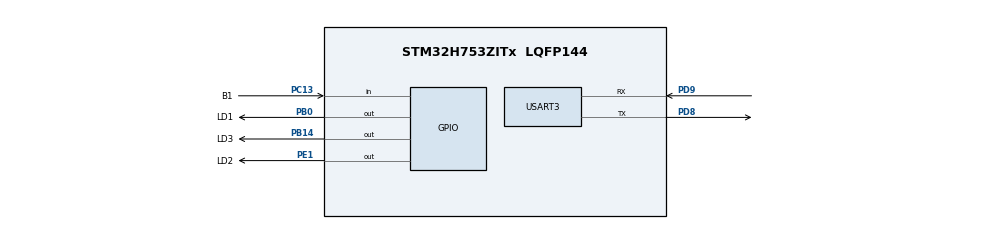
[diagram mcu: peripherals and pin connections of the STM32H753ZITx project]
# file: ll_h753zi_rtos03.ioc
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Mcu.Family=STM32H7
Mcu.Name=STM32H753ZITx
Mcu.Package=LQFP144
NVIC.PriorityGroup=NVIC_PRIORITYGROUP_4
PB0.GPIO_Label=LD1
PB0.Signal=GPIO_Output
PB14.GPIO_Label=LD3
PB14.Signal=GPIO_Output
PC13.GPIO_Label=B1
PC13.Signal=GPIO_Input
PD8.Mode=Asynchronous
PD8.Signal=USART3_TX
PD9.Mode=Asynchronous
PD9.Signal=USART3_RX
PE1.GPIO_Label=LD2
PE1.Signal=GPIO_Output
ProjectManager.HeapSize=0x200
ProjectManager.StackSize=0x400
ProjectManager.TargetToolchain=STM32CubeIDE
RCC.ADCFreq_Value=129000000
RCC.APB1Freq_Value=120000000
RCC.APB2Freq_Value=120000000
RCC.APB3Freq_Value=120000000
RCC.APB4Freq_Value=120000000
RCC.CortexFreq_Value=480000000
RCC.D1PPRE=RCC_APB3_DIV2
RCC.D2PPRE1=RCC_APB1_DIV2
RCC.D2PPRE2=RCC_APB2_DIV2
RCC.D3PPRE=RCC_APB4_DIV2
RCC.DIVM1=4
RCC.DIVN1=60
RCC.HCLKFreq_Value=240000000
RCC.HPRE=RCC_HCLK_DIV2
RCC.PLLFRACN=0
RCC.SYSCLKFreq_VALUE=480000000
RCC.SYSCLKSource=RCC_SYSCLKSOURCE_PLLCLK
RCC.USBFreq_Value=480000000
USART3.VirtualMode-Asynchronous=VM_ASYNC
VP_MEMORYMAP_VS_MEMORYMAP.Mode=CurAppReg
board=custom

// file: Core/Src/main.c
/* USER CODE BEGIN Header */
/**
  ******************************************************************************
  * @file           : main.c
  * @brief          : Main program body
  ******************************************************************************
  * @attention
  *
  * Copyright (c) 2024 STMicroelectronics.
  * All rights reserved.
  *
  * This software is licensed under terms that can be found in the LICENSE file
  * in the root directory of this software component.
  * If no LICENSE file comes with this software, it is provided AS-IS.
  *
  ******************************************************************************
  */
/* USER CODE END Header */
#include "main.h"

void SystemClock_Config(void);
static void MX_GPIO_Init(void);
static void MX_USART3_UART_Init(void);

int main(void)
{

  /* MCU Configuration--------------------------------------------------------*/

  /* Reset of all peripherals, Initializes the Flash interface and the Systick. */
  LL_APB4_GRP1_EnableClock(LL_APB4_GRP1_PERIPH_SYSCFG);

  /* System interrupt init*/
  NVIC_SetPriorityGrouping(NVIC_PRIORITYGROUP_4);

  /* SysTick_IRQn interrupt configuration */
  NVIC_SetPriority(SysTick_IRQn, NVIC_EncodePriority(NVIC_GetPriorityGrouping(),15, 0));

  /* Configure the system clock */
  SystemClock_Config();

  /* Initialize all configured peripherals */
  MX_GPIO_Init();
  MX_USART3_UART_Init();
  /* USER CODE BEGIN 2 */
	LL_SYSTICK_EnableIT();
	main_rtos();
  /* USER CODE END 2 */

  /* Infinite loop */
	while (1) {

    /* USER CODE BEGIN 3 */
		LL_GPIO_TogglePin(LD1_GPIO_Port, LD1_Pin);
		LL_GPIO_TogglePin(LD2_GPIO_Port, LD2_Pin);
		LL_GPIO_TogglePin(LD3_GPIO_Port, LD3_Pin);
		if (LL_USART_IsActiveFlag_TXE_TXFNF(USART3)) {
			LL_USART_TransmitData8(USART3, 'u');
		}
		LL_mDelay(500);
	}
  /* USER CODE END 3 */
}

void SystemClock_Config(void)
{
  LL_FLASH_SetLatency(LL_FLASH_LATENCY_4);
  while(LL_FLASH_GetLatency()!= LL_FLASH_LATENCY_4)
  {
  }
  LL_PWR_ConfigSupply(LL_PWR_LDO_SUPPLY);
  LL_PWR_SetRegulVoltageScaling(LL_PWR_REGU_VOLTAGE_SCALE0);
  while (LL_PWR_IsActiveFlag_VOS() == 0)
  {
  }
  LL_RCC_HSI_Enable();

   /* Wait till HSI is ready */
  while(LL_RCC_HSI_IsReady() != 1)
  {

  }
  LL_RCC_HSI_SetCalibTrimming(64);
  LL_RCC_HSI_SetDivider(LL_RCC_HSI_DIV1);
  LL_RCC_PLL_SetSource(LL_RCC_PLLSOURCE_HSI);
  LL_RCC_PLL1P_Enable();
  LL_RCC_PLL1_SetVCOInputRange(LL_RCC_PLLINPUTRANGE_8_16);
  LL_RCC_PLL1_SetVCOOutputRange(LL_RCC_PLLVCORANGE_WIDE);
  LL_RCC_PLL1_SetM(4);
  LL_RCC_PLL1_SetN(60);
  LL_RCC_PLL1_SetP(2);
  LL_RCC_PLL1_SetQ(2);
  LL_RCC_PLL1_SetR(2);
  LL_RCC_PLL1_Enable();

   /* Wait till PLL is ready */
  while(LL_RCC_PLL1_IsReady() != 1)
  {
  }

   /* Intermediate AHB prescaler 2 when target frequency clock is higher than 80 MHz */
   LL_RCC_SetAHBPrescaler(LL_RCC_AHB_DIV_2);

  LL_RCC_SetSysClkSource(LL_RCC_SYS_CLKSOURCE_PLL1);

   /* Wait till System clock is ready */
  while(LL_RCC_GetSysClkSource() != LL_RCC_SYS_CLKSOURCE_STATUS_PLL1)
  {

  }
  LL_RCC_SetSysPrescaler(LL_RCC_SYSCLK_DIV_1);
  LL_RCC_SetAHBPrescaler(LL_RCC_AHB_DIV_2);
  LL_RCC_SetAPB1Prescaler(LL_RCC_APB1_DIV_2);
  LL_RCC_SetAPB2Prescaler(LL_RCC_APB2_DIV_2);
  LL_RCC_SetAPB3Prescaler(LL_RCC_APB3_DIV_2);
  LL_RCC_SetAPB4Prescaler(LL_RCC_APB4_DIV_2);

  LL_Init1msTick(480000000);

  LL_SetSystemCoreClock(480000000);
}

static void MX_USART3_UART_Init(void)
{

  LL_USART_InitTypeDef USART_InitStruct = {0};

  LL_GPIO_InitTypeDef GPIO_InitStruct = {0};

  LL_RCC_SetUSARTClockSource(LL_RCC_USART234578_CLKSOURCE_PCLK1);

  /* Peripheral clock enable */
  LL_APB1_GRP1_EnableClock(LL_APB1_GRP1_PERIPH_USART3);

  LL_AHB4_GRP1_EnableClock(LL_AHB4_GRP1_PERIPH_GPIOD);
  /**USART3 GPIO Configuration
  PD8   ------> USART3_TX
  PD9   ------> USART3_RX
  */
  GPIO_InitStruct.Pin = LL_GPIO_PIN_8|LL_GPIO_PIN_9;
  GPIO_InitStruct.Mode = LL_GPIO_MODE_ALTERNATE;
  GPIO_InitStruct.Speed = LL_GPIO_SPEED_FREQ_LOW;
  GPIO_InitStruct.OutputType = LL_GPIO_OUTPUT_PUSHPULL;
  GPIO_InitStruct.Pull = LL_GPIO_PULL_NO;
  GPIO_InitStruct.Alternate = LL_GPIO_AF_7;
  LL_GPIO_Init(GPIOD, &GPIO_InitStruct);

  USART_InitStruct.PrescalerValue = LL_USART_PRESCALER_DIV1;
  USART_InitStruct.BaudRate = 115200;
  USART_InitStruct.DataWidth = LL_USART_DATAWIDTH_8B;
  USART_InitStruct.StopBits = LL_USART_STOPBITS_1;
  USART_InitStruct.Parity = LL_USART_PARITY_NONE;
  USART_InitStruct.TransferDirection = LL_USART_DIRECTION_TX_RX;
  USART_InitStruct.HardwareFlowControl = LL_USART_HWCONTROL_NONE;
  USART_InitStruct.OverSampling = LL_USART_OVERSAMPLING_16;
  LL_USART_Init(USART3, &USART_InitStruct);
  LL_USART_SetTXFIFOThreshold(USART3, LL_USART_FIFOTHRESHOLD_1_8);
  LL_USART_SetRXFIFOThreshold(USART3, LL_USART_FIFOTHRESHOLD_1_8);
  LL_USART_DisableFIFO(USART3);
  LL_USART_ConfigAsyncMode(USART3);

  LL_USART_Enable(USART3);

  /* Polling USART3 initialisation */
  while((!(LL_USART_IsActiveFlag_TEACK(USART3))) || (!(LL_USART_IsActiveFlag_REACK(USART3))))
  {
  }

}

static void MX_GPIO_Init(void)
{
  LL_EXTI_InitTypeDef EXTI_InitStruct = {0};
  LL_GPIO_InitTypeDef GPIO_InitStruct = {0};

  /* GPIO Ports Clock Enable */
  LL_AHB4_GRP1_EnableClock(LL_AHB4_GRP1_PERIPH_GPIOC);
  LL_AHB4_GRP1_EnableClock(LL_AHB4_GRP1_PERIPH_GPIOB);
  LL_AHB4_GRP1_EnableClock(LL_AHB4_GRP1_PERIPH_GPIOD);
  LL_AHB4_GRP1_EnableClock(LL_AHB4_GRP1_PERIPH_GPIOE);

  /**/
  LL_GPIO_ResetOutputPin(GPIOB, LD1_Pin|LD3_Pin);

  /**/
  LL_GPIO_ResetOutputPin(LD2_GPIO_Port, LD2_Pin);

  /**/
  LL_SYSCFG_SetEXTISource(LL_SYSCFG_EXTI_PORTC, LL_SYSCFG_EXTI_LINE13);

  /**/
  EXTI_InitStruct.Line_0_31 = LL_EXTI_LINE_13;
  EXTI_InitStruct.Line_32_63 = LL_EXTI_LINE_NONE;
  EXTI_InitStruct.Line_64_95 = LL_EXTI_LINE_NONE;
  EXTI_InitStruct.LineCommand = ENABLE;
  EXTI_InitStruct.Mode = LL_EXTI_MODE_IT;
  EXTI_InitStruct.Trigger = LL_EXTI_TRIGGER_RISING;
  LL_EXTI_Init(&EXTI_InitStruct);

  /**/
  LL_GPIO_SetPinPull(B1_GPIO_Port, B1_Pin, LL_GPIO_PULL_NO);

  /**/
  LL_GPIO_SetPinMode(B1_GPIO_Port, B1_Pin, LL_GPIO_MODE_INPUT);

  /**/
  GPIO_InitStruct.Pin = LD1_Pin|LD3_Pin;
  GPIO_InitStruct.Mode = LL_GPIO_MODE_OUTPUT;
  GPIO_InitStruct.Speed = LL_GPIO_SPEED_FREQ_LOW;
  GPIO_InitStruct.OutputType = LL_GPIO_OUTPUT_PUSHPULL;
  GPIO_InitStruct.Pull = LL_GPIO_PULL_NO;
  LL_GPIO_Init(GPIOB, &GPIO_InitStruct);

  /**/
  GPIO_InitStruct.Pin = LD2_Pin;
  GPIO_InitStruct.Mode = LL_GPIO_MODE_OUTPUT;
  GPIO_InitStruct.Speed = LL_GPIO_SPEED_FREQ_LOW;
  GPIO_InitStruct.OutputType = LL_GPIO_OUTPUT_PUSHPULL;
  GPIO_InitStruct.Pull = LL_GPIO_PULL_NO;
  LL_GPIO_Init(LD2_GPIO_Port, &GPIO_InitStruct);

}

void Error_Handler(void)
{
  __disable_irq();
  while (1)
  {
  }
}
